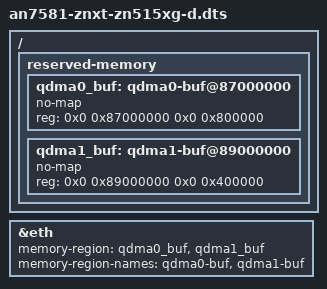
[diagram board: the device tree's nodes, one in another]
// SPDX-License-Identifier: (GPL-2.0-only OR BSD-2-Clause)
/dts-v1/;

/* Firmware reserves the first 2 MiB of DRAM. */
/memreserve/ 0x80000000 0x200000;

#include "an7581-znxt-zn515xg-d.dtsi"

/*
 * Default QDMA hardware-forwarding buffer profile: 4096 descriptors per
 * engine.  airoha_qdma_init_hfwd_queues() computes the count as
 * div_u64(reserved_size, buf_size), with buf_size 2048 B on QDMA0 and 1024 B
 * on QDMA1, so this needs 8 MiB + 4 MiB.
 *
 * The other two profiles are separate configurations in the same FIT
 * (mem8192, mem16384).  U-Boot picks one through the `bootconf` variable and
 * the plain `bootm <addr>#<conf>` syntax - no overlay stacking involved.
 *
 * QDMA1 stays at 0x89000000 in every profile because the 16384 profile lets
 * QDMA0 run all the way up to that address.
 */
/ {
	reserved-memory {
		qdma0_buf: qdma0-buf@87000000 {
			no-map;
			reg = <0x0 0x87000000 0x0 0x800000>;
		};

		qdma1_buf: qdma1-buf@89000000 {
			no-map;
			reg = <0x0 0x89000000 0x0 0x400000>;
		};
	};
};

&eth {
	memory-region = <&qdma0_buf>, <&qdma1_buf>;
	memory-region-names = "qdma0-buf", "qdma1-buf";
};
